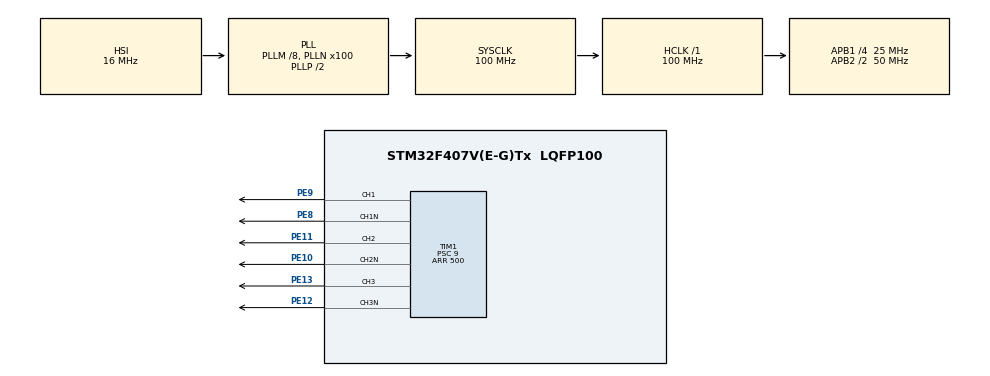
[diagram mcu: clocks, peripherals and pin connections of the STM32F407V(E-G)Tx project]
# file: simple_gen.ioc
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Mcu.Family=STM32F4
Mcu.Name=STM32F407V(E-G)Tx
Mcu.Package=LQFP100
NVIC.PriorityGroup=NVIC_PRIORITYGROUP_4
NVIC.TIM6_DAC_IRQn=true\:0\:0\:false\:false\:true\:true\:true
PA13.Mode=Serial_Wire
PA13.Signal=SYS_JTMS-SWDIO
PA14.Mode=Serial_Wire
PA14.Signal=SYS_JTCK-SWCLK
PE10.Mode=PWM Generation2 CH2 CH2N
PE10.Signal=TIM1_CH2N
PE11.Signal=S_TIM1_CH2
PE12.Mode=PWM Generation3 CH3 CH3N
PE12.Signal=TIM1_CH3N
PE13.Signal=S_TIM1_CH3
PE8.Mode=PWM Generation1 CH1 CH1N
PE8.Signal=TIM1_CH1N
PE9.Signal=S_TIM1_CH1
ProjectManager.HeapSize=0xA00
ProjectManager.StackSize=0xFF0
ProjectManager.TargetToolchain=MDK-ARM V5.27
RCC.48MHZClocksFreq_Value=50000000
RCC.AHBFreq_Value=100000000
RCC.APB1CLKDivider=RCC_HCLK_DIV4
RCC.APB1Freq_Value=25000000
RCC.APB1TimFreq_Value=50000000
RCC.APB2CLKDivider=RCC_HCLK_DIV2
RCC.APB2Freq_Value=50000000
RCC.APB2TimFreq_Value=100000000
RCC.CortexFreq_Value=100000000
RCC.HCLKFreq_Value=100000000
RCC.HSE_VALUE=25000000
RCC.HSI_VALUE=16000000
RCC.LSE_VALUE=32768
RCC.PLLM=8
RCC.PLLN=100
RCC.SYSCLKFreq_VALUE=100000000
RCC.SYSCLKSource=RCC_SYSCLKSOURCE_PLLCLK
RCC.VCOOutputFreq_Value=200000000
SH.S_TIM1_CH1.0=TIM1_CH1,PWM Generation1 CH1 CH1N
SH.S_TIM1_CH2.0=TIM1_CH2,PWM Generation2 CH2 CH2N
SH.S_TIM1_CH3.0=TIM1_CH3,PWM Generation3 CH3 CH3N
TIM1.Channel-PWM\ Generation1\ CH1\ CH1N=TIM_CHANNEL_1
TIM1.Channel-PWM\ Generation2\ CH2\ CH2N=TIM_CHANNEL_2
TIM1.Channel-PWM\ Generation3\ CH3\ CH3N=TIM_CHANNEL_3
TIM1.ClockDivision=TIM_CLOCKDIVISION_DIV4
TIM1.DeadTime=15
TIM1.Period=500
TIM1.Prescaler=9
TIM6.Period=1000
TIM6.Prescaler=499
VP_TIM1_VS_ClockSourceINT.Mode=Internal
VP_TIM6_VS_ClockSourceINT.Mode=Enable_Timer
board=custom

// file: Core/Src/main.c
/* USER CODE BEGIN Header */
/**
  ******************************************************************************
  * @file           : main.c
  * @brief          : Main program body
  ******************************************************************************
  * @attention
  *
  * <h2><center>&copy; Copyright (c) 2021 STMicroelectronics.
  * All rights reserved.</center></h2>
  *
  * This software component is licensed by ST under BSD 3-Clause license,
  * the "License"; You may not use this file except in compliance with the
  * License. You may obtain a copy of the License at:
  *                        opensource.org/licenses/BSD-3-Clause
  *
  ******************************************************************************
  */
/* USER CODE END Header */
#include "main.h"
#include "tim.h"
#include "gpio.h"

void SystemClock_Config(void);

int main(void)
{

  /* MCU Configuration--------------------------------------------------------*/

  /* Reset of all peripherals, Initializes the Flash interface and the Systick. */
  HAL_Init();

  /* Configure the system clock */
  SystemClock_Config();

  /* Initialize all configured peripherals */
  MX_GPIO_Init();
  MX_TIM1_Init();
  MX_TIM6_Init();

  /* USER CODE BEGIN 2 */
	HAL_Delay(2500); //задержка на всякий случай

	//Обнуляем значения скважности всех 3 каналов
	__HAL_TIM_SetCompare(&htim1, PWM_A_CH, 0);
	__HAL_TIM_SetCompare(&htim1, PWM_A_CH, 0);
	__HAL_TIM_SetCompare(&htim1, PWM_A_CH, 0);

	//Запускаем таймеры, частота ШИМ 20 кГц
	HAL_TIM_PWM_Start(&htim1, PWM_A_CH);
	HAL_TIM_PWM_Start(&htim1, PWM_B_CH);
	HAL_TIM_PWM_Start(&htim1, PWM_C_CH);
	HAL_TIMEx_PWMN_Start(&htim1, PWM_A_CH);
	HAL_TIMEx_PWMN_Start(&htim1, PWM_B_CH);
	HAL_TIMEx_PWMN_Start(&htim1, PWM_C_CH);

	//Запускаем основной таймер, который отвечает за частоту смены положения вектора напряжения
	//Устанавливаем значение ARR  100000(неизменно)/1000(можно менять) = 100 Гц - частота "вращения" вектора напряжения
	__HAL_TIM_SetAutoreload(&htim6, 1000);
	HAL_TIM_Base_Start_IT(&htim6);
  /* USER CODE END 2 */

  /* Infinite loop */
  while (1)
  {

  }
}

void SystemClock_Config(void)
{
  RCC_OscInitTypeDef RCC_OscInitStruct = {0};
  RCC_ClkInitTypeDef RCC_ClkInitStruct = {0};

  /** Configure the main internal regulator output voltage
  */
  __HAL_RCC_PWR_CLK_ENABLE();
  __HAL_PWR_VOLTAGESCALING_CONFIG(PWR_REGULATOR_VOLTAGE_SCALE1);
  /** Initializes the RCC Oscillators according to the specified parameters
  * in the RCC_OscInitTypeDef structure.
  */
  RCC_OscInitStruct.OscillatorType = RCC_OSCILLATORTYPE_HSI;
  RCC_OscInitStruct.HSIState = RCC_HSI_ON;
  RCC_OscInitStruct.HSICalibrationValue = RCC_HSICALIBRATION_DEFAULT;
  RCC_OscInitStruct.PLL.PLLState = RCC_PLL_ON;
  RCC_OscInitStruct.PLL.PLLSource = RCC_PLLSOURCE_HSI;
  RCC_OscInitStruct.PLL.PLLM = 8;
  RCC_OscInitStruct.PLL.PLLN = 100;
  RCC_OscInitStruct.PLL.PLLP = RCC_PLLP_DIV2;
  RCC_OscInitStruct.PLL.PLLQ = 4;
  if (HAL_RCC_OscConfig(&RCC_OscInitStruct) != HAL_OK)
  {
    Error_Handler();
  }
  /** Initializes the CPU, AHB and APB buses clocks
  */
  RCC_ClkInitStruct.ClockType = RCC_CLOCKTYPE_HCLK|RCC_CLOCKTYPE_SYSCLK
                              |RCC_CLOCKTYPE_PCLK1|RCC_CLOCKTYPE_PCLK2;
  RCC_ClkInitStruct.SYSCLKSource = RCC_SYSCLKSOURCE_PLLCLK;
  RCC_ClkInitStruct.AHBCLKDivider = RCC_SYSCLK_DIV1;
  RCC_ClkInitStruct.APB1CLKDivider = RCC_HCLK_DIV4;
  RCC_ClkInitStruct.APB2CLKDivider = RCC_HCLK_DIV2;

  if (HAL_RCC_ClockConfig(&RCC_ClkInitStruct, FLASH_LATENCY_3) != HAL_OK)
  {
    Error_Handler();
  }
}

/* USER CODE BEGIN 4 */
void HAL_TIM_PeriodElapsedCallback(TIM_HandleTypeDef* htim)
{
	if(htim == &htim6)
	{

	}
}
/* USER CODE END 4 */

void Error_Handler(void)
{
  __disable_irq();
  while (1)
  {
  }
}

/************************ (C) COPYRIGHT STMicroelectronics *****END OF FILE****/
